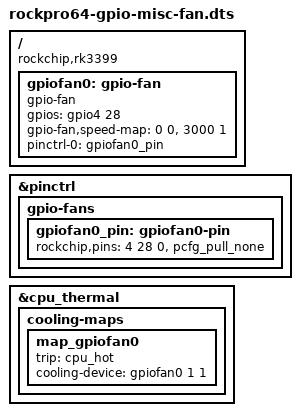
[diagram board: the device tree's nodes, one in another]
/* For Pine RockPro64 boards only!! */

/dts-v1/;
/plugin/;

/ {
    compatible = "rockchip,rk3399";

    /* 1. Pin Control - Create as many 'gpiofanX_pins' as you have gpio-controlled fans, incrementing X as needed */
    fragment@20 {
        target = <&pinctrl>;
        __overlay__ {
            gpio-fans {
                gpiofan0_pin: gpiofan0-pin {
                    rockchip,pins = <4 28 0 &pcfg_pull_none>;
                };
            };
        };
    };

    /* 2. The Fan Device - Using the dedicated gpio-fan driver, again, create as many gpiofanX, incrementing as needed */
    fragment@21 {
        target-path = "/";
        __overlay__ {
            gpiofan0: gpio-fan {
                compatible = "gpio-fan";
                gpios = <&gpio4 28 0>;
                gpio-fan,speed-map = <0 0>, <3000 1>;
                #cooling-cells = <2>;
                pinctrl-names = "default";
                pinctrl-0 = <&gpiofan0_pin>;
                status = "okay";
            };
        };
    };

    /* 3: Use the &cpu_thermal label to merge the map correctly, one map for each fan */
    fragment@22 {
        target = <&cpu_thermal>;
        __overlay__ {
            cooling-maps {
                map_gpiofan0 {
                    trip = <&cpu_hot>;
                    cooling-device = <&gpiofan0 1 1>;
                };
            };
        };
    };
};

/* 
	Defaults to GPIO4_D4 (bank 4, offset 28) aka  pin 31 (gpio 156)

	# Check if the cooling device is registered
	ls /sys/class/thermal/cooling_device*

	# Find which one is 'gpio-fan'
	for fan in /sys/class/thermal/cooling_device*; do echo $fan; cat ${fan}/type; done

	# Manually override to test the fan (if permissions allow)
	echo 1 > /sys/class/thermal/cooling_device${fan}/cur_state

        ## To install:

        * dtc -@ -I dts -O dtb -o /boot/dtb/rockchip/overlay/rockchip-gpio-misc-fan.dtbo rockpro64-gpio-misc-fan.dts

        *  Edit /boot/orangepiEnv.txt and add
                overlays=gpio-misc-fan   ( or:  orverlays=[existing] gpio-misc-fan )

        *  reboot

*/
